# FM33L0XX register map
File version: 1.0
CPU: SC000 r1p0, little endian, no MPU, no FPU, 3 interrupt priority bits
Registers are 32-bit, read-write, reset 0x0 unless marked. A register's access mark holds for its fields unless they carry their own. Offsets are from the block's base; [hi:lo] are bit positions; {n}, {i} and the like mark numbered series; 'fields as' and 'values as' point back to an identical list.

## DMA — Peripheral DMA, Direct Memory Access
Base 0x40000400
0x00 GCR — Global Control Register
  [0] EN — DMA Global enable bit
    0=DISABLE (DMA is disable); 1=ENABLE (DMA is enable)
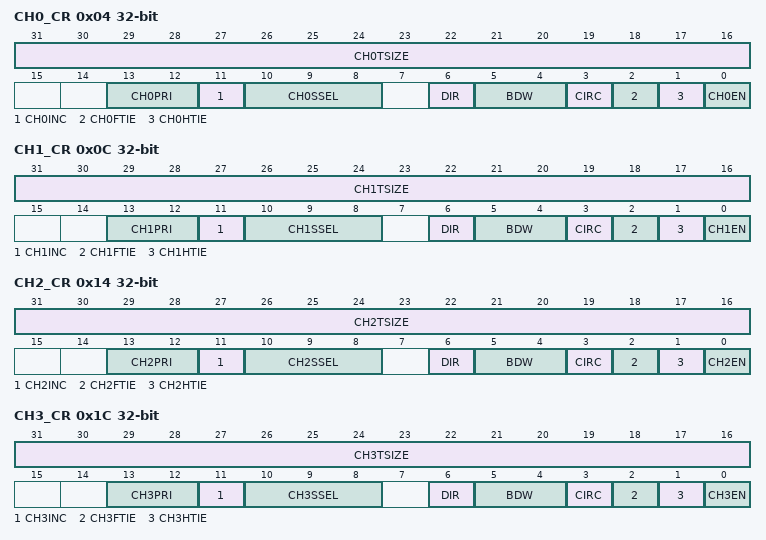
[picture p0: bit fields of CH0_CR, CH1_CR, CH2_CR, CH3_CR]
0x04 CH0_CR — DMA CH0 control Register
  [31:16] CH0TSIZE — channel0 transmit size setting
  [13:12] CH0PRI — channel0 priority setting
    0=LOW (channel0's priority is low); 1=Medium (channel0's priority is Medium); 2=High (channel0's priority is High); 3=Very High (channel0's priority is Very High)
  [11] CH0INC — channel0 RAM address increase setting
    0=DECREASE (channel0 RAM address decrease); 1=INCREASE (channel0 RAM address increase)
  [10:8] CH0SSEL — channel0 periph source select
    0=ADC (ADC data); 1=LPUART0_RX (LPUART0_RX data); 2=LPUART1_TX (LPUART1_TX data); 3=AES_IN (AES_IN data); 4=CRC (CRC data); 5=ATIM_CH1 (ATIM_CH1 data); 6=GTIM0_CH1 (GTIM0_CH1 data); 7=GTIM1_CH1 (GTIM1_CH1 data)
  [6] DIR — transfer direction
    0=perip to ram; 1=ram to perip
  [5:4] BDW — byte width select
    0=byte; 1=half_word; 1=word
  [3] CIRC — CIRC EN
    0=DISABLE (CIRC disable); 1=ENABLE (CIRC enable)
  [2] CH0FTIE — channel0 full transmit interrupt enable bit
    0=DISABLE (CH0 full transmit interrupt disable); 1=ENABLE (CH0 full transmit interrupt enable)
  [1] CH0HTIE — channel0 half transmit interrupt enable bit
    0=DISABLE (CH0 half transmit interrupt disable); 1=ENABLE (CH0 half transmit interrupt enable)
  [0] CH0EN — channel0 enable bit
    0=DISABLE (CH0 disable); 1=ENABLE (CH0 enable)
0x08 CH0_MAD — DMA channel0 RAM address Register
  [31:0] CH0RAMAD — CH0 RAM address
0x0C CH1_CR — DMA CH1 control Register
  [31:16] CH1TSIZE — channel1 transmit size setting
  [13:12] CH1PRI — channel1 priority setting
    0=LOW (channel1's priority is low); 1=Medium (channel1's priority is Medium); 2=High (channel1's priority is High); 3=Very High (channel1's priority is Very High)
  [11] CH1INC — channel1 RAM address increase setting
    0=DECREASE (channel1 RAM address decrease); 1=INCREASE (channel1 RAM address increase)
  [10:8] CH1SSEL — channel1 periph source select
    0=RXD0 (UART0_RXD data); 1=LPUART0_TX (LPUART0_TX data); 2=I2C_RX (I2C_RX data); 3=AES_OUT (AES_OUT data); 4=ATIM_CH2 (ATIM_CH2 data); 5=GTIM0_CH2 (GTIM0_CH2 data); 6=GTIM1_CH2 (GTIM1_CH2 data); 7=LPT32_CH1 (LPT32_CH1 data)
  [6] DIR — transfer direction
    0=perip to ram; 1=ram to perip
  [5:4] BDW — byte width select
    0=byte; 1=half_word; 1=word
  [3] CIRC — CIRC EN
    0=DISABLE (CIRC disable); 1=ENABLE (CIRC enable)
  [2] CH1FTIE — channel1 full transmit interrupt enable bit
    0=DISABLE (CH1 full transmit interrupt disable); 1=ENABLE (CH1 full transmit interrupt enable)
  [1] CH1HTIE — channel1 half transmit interrupt enable bit
    0=DISABLE (CH1 half transmit interrupt disable); 1=ENABLE (CH1 half transmit interrupt enable)
  [0] CH1EN — channel1 enable bit
    0=DISABLE (CH1 disable); 1=ENABLE (CH1 enable)
0x10 CH1_MAD — DMA channel1 RAM address Register
  [31:0] CH1MEMAD — CH1 RAM address
0x14 CH2_CR — DMA CH2 control Register
  [31:16] CH2TSIZE — channel2 transmit size setting
  [13:12] CH2PRI — channel2 priority setting
    0=LOW (channel2's priority is low); 1=Medium (channel2's priority is Medium); 2=High (channel2's priority is High); 3=Very High (channel2's priority is Very High)
  [11] CH2INC — channel2 RAM address increase setting
    0=DECREASE (channel2 RAM address decrease); 1=INCREASE (channel2 RAM address increase)
  [10:8] CH2SSEL — channel2 periph source select
    0=SPI2_RX (SPI2_RX data); 1=TXD0 (UART0_TXD data); 2=RXD4 (UART4_RXD data); 3=LPUART1_RX (LPUART1_RX data); 4=I2C_TX (I2C_TX data); 5=ATIM_CH3 (ATIM_CH3 data); 6=GTIM0_CH3 (GTIM0_CH3 data); 7=GTIM1_CH3 (GTIM1_CH3 data)
  [6] DIR — transfer direction
    0=perip to ram; 1=ram to perip
  [5:4] BDW — byte width select
    0=byte; 1=half_word; 1=word
  [3] CIRC — CIRC EN
    0=DISABLE (CIRC disable); 1=ENABLE (CIRC enable)
  [2] CH2FTIE — channel2 full transmit interrupt enable bit
    0=DISABLE (CH2 full transmit interrupt disable); 1=ENABLE (CH2 full transmit interrupt enable)
  [1] CH2HTIE — channel2 half transmit interrupt enable bit
    0=DISABLE (CH2 half transmit interrupt disable); 1=ENABLE (CH2 half transmit interrupt enable)
  [0] CH2EN — channel2 enable bit
    0=DISABLE (CH2 disable); 1=ENABLE (CH2 enable)
0x18 CH2_MAD — DMA channel2 RAM address Register
  [31:0] CH2RAMAD — CH2 RAM address
0x1C CH3_CR — DMA CH3 control Register
  [31:16] CH3TSIZE — channel3 transmit size setting
  [13:12] CH3PRI — channel3 priority setting
    0=LOW (channel3's priority is low); 1=Medium (channel3's priority is Medium); 2=High (channel3's priority is High); 3=Very High (channel3's priority is Very High)
  [11] CH3INC — channel3 RAM address increase setting
    0=DECREASE (channel3 RAM address decrease); 1=INCREASE (channel3 RAM address increase)
  [10:8] CH3SSEL — channel3 periph source select
    0=SPI1_RX (SPI1_RX data); 1=RXD0 (UART0_RXD data); 2=RXD1 (UART1_RXD data); 3=TXD4 (UART4_TXD data); 4=LPUART0_RX (LPUART0_RX data); 5=ATIM_CH4 (ATIM_CH4 data); 6=GTIM1_CH4 (GTIM0_CH4 data); 7=GTIM2_CH4 (GTIM1_CH4 data)
  [6] DIR — transfer direction
    0=perip to ram; 1=ram to perip
  [5:4] BDW — byte width select
    0=byte; 1=half_word; 1=word
  [3] CIRC — CIRC EN
    0=DISABLE (CIRC disable); 1=ENABLE (CIRC enable)
  [2] CH3FTIE — channel3 full transmit interrupt enable bit
    0=DISABLE (CH3 full transmit interrupt disable); 1=ENABLE (CH3 full transmit interrupt enable)
  [1] CH3HTIE — channel3 half transmit interrupt enable bit
    0=DISABLE (CH3 half transmit interrupt disable); 1=ENABLE (CH3 half transmit interrupt enable)
  [0] CH3EN — channel3 enable bit
    0=DISABLE (CH3 disable); 1=ENABLE (CH3 enable)
0x20 CH3_AD — DMA channel3 RAM address Register
  [31:0] CH3MEMAD — CH3 RAM address
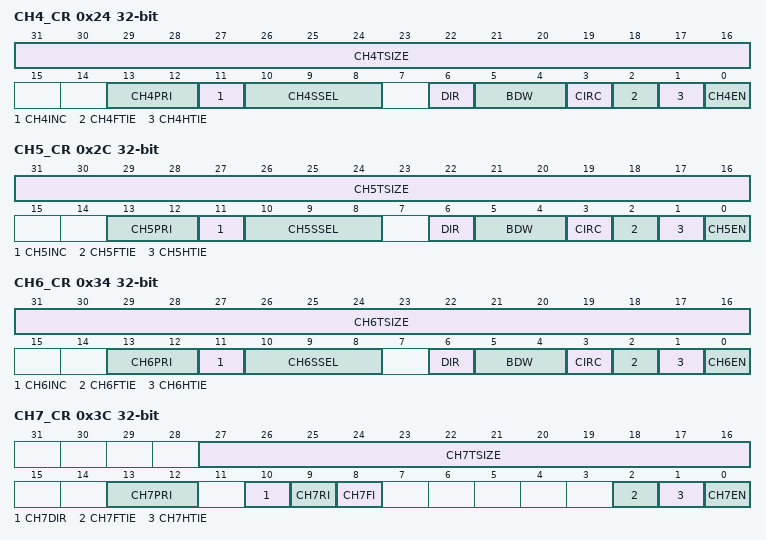
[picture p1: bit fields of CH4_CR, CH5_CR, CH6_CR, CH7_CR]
0x24 CH4_CR — DMA CH4 control Register
  [31:16] CH4TSIZE — channel4 transmit size setting
  [13:12] CH4PRI — channel4 priority setting
    0=LOW (channel4's priority is low); 1=Medium (channel4's priority is Medium); 2=High (channel4's priority is High); 3=Very High (channel4's priority is Very High)
  [11] CH4INC — channel4 RAM address increase setting
    0=DECREASE (channel4 RAM address decrease); 1=INCREASE (channel4 RAM address increase)
  [10:8] CH4SSEL — channel4 periph source select
    0=ADC (ADC data); 1=SPI1_TX (SPI1_TX data); 2=SPI2_TX (SPI2_TX data); 3=TXD0 (UART0_TXD data); 4=TXD1 (UART1_TXD data); 5=RXD5 (UART5_RXD data); 6=I2C_RX (I2C_RX data); 7=ATIM_TRIG (ATIM_TRIG data)
  [6] DIR — transfer direction
    0=perip to ram; 1=ram to perip
  [5:4] BDW — byte width select
    0=byte; 1=half_word; 1=word
  [3] CIRC — CIRC EN
    0=DISABLE (CIRC disable); 1=ENABLE (CIRC enable)
  [2] CH4FTIE — channel4 full transmit interrupt enable bit
    0=DISABLE (CH4 full transmit interrupt disable); 1=ENABLE (CH4 full transmit interrupt enable)
  [1] CH4HTIE — channel4 half transmit interrupt enable bit
    0=DISABLE (CH4 half transmit interrupt disable); 1=ENABLE (CH4 half transmit interrupt enable)
  [0] CH4EN — channel4 enable bit
    0=DISABLE (CH4 disable); 1=ENABLE (CH4 enable)
{0x8+8i} CH{i}_MAD (i=4..6) — DMA channel{i} RAM address Register
  [31:0] CH{i}MEMAD — CH{i} RAM address
0x2C CH5_CR — DMA CH5 control Register
  [31:16] CH5TSIZE — channel5 transmit size setting
  [13:12] CH5PRI — channel5 priority setting
    0=LOW (channel5's priority is low); 1=Medium (channel5's priority is Medium); 2=High (channel5's priority is High); 3=Very High (channel5's priority is Very High)
  [11] CH5INC — channel5 RAM address increase setting
    0=DECREASE (channel5 RAM address decrease); 1=INCREASE (channel5 RAM address increase)
  [10:8] CH5SSEL — channel5 periph source select
    0=SPI1_RX (SPI1_RX data); 1=SPI2_RX (SPI2_RX data); 2=RXD1 (UART1_RXD data); 3=LPUART0_TX (LPUART0_TX data); 4=LPUART1_RX (LPUART1_RX data); 5=U7816RX (U7816RX data); 6=GTIM1_TRI (GTIM1_TRI data); 7=LPT32_CH2 (LPT32_CH2 data)
  [6] DIR — transfer direction
    0=perip to ram; 1=ram to perip
  [5:4] BDW — byte width select
    0=byte; 1=half_word; 1=word
  [3] CIRC — CIRC EN
    0=DISABLE (CIRC disable); 1=ENABLE (CIRC enable)
  [2] CH5FTIE — channel5 full transmit interrupt enable bit
    0=DISABLE (CH5 full transmit interrupt disable); 1=ENABLE (CH5 full transmit interrupt enable)
  [1] CH5HTIE — channel5 half transmit interrupt enable bit
    0=DISABLE (CH5 half transmit interrupt disable); 1=ENABLE (CH5 half transmit interrupt enable)
  [0] CH5EN — channel5 enable bit
    0=DISABLE (CH5 disable); 1=ENABLE (CH5 enable)
0x34 CH6_CR — DMA CH6 control Register
  [31:16] CH6TSIZE — channel6 transmit size setting
  [13:12] CH6PRI — channel6 priority setting
    0=LOW (channel6's priority is low); 1=Medium (channel6's priority is Medium); 2=High (channel6's priority is High); 3=Very High (channel6's priority is Very High)
  [11] CH6INC — channel6 RAM address increase setting
    0=DECREASE (channel6 RAM address decrease); 1=INCREASE (channel6 RAM address increase)
  [10:8] CH6SSEL — channel6 periph source select
    0=SPI1_TX (SPI1_TX data); 1=SPI2_TX (SPI2_TX data); 2=TXD1 (UART1_TXD data); 3=TXD5 (UART5_TXD data); 4=LPUART1_TX (LPUART1_TX data); 5=U7816TX (U7816TX data); 6=I2C_TX (I2C_TX data); 7=GTIM_TRIG (GTIM_TRIG data)
  [6] DIR — transfer direction
    0=perip to ram; 1=ram to perip
  [5:4] BDW — byte width select
    0=byte; 1=half_word; 1=word
  [3] CIRC — CIRC EN
    0=DISABLE (CIRC disable); 1=ENABLE (CIRC enable)
  [2] CH6FTIE — channel6 full transmit interrupt enable bit
    0=DISABLE (CH6 full transmit interrupt disable); 1=ENABLE (CH6 full transmit interrupt enable)
  [1] CH6HTIE — channel6 half transmit interrupt enable bit
    0=DISABLE (CH6 half transmit interrupt disable); 1=ENABLE (CH6 half transmit interrupt enable)
  [0] CH6EN — channel6 enable bit
    0=DISABLE (CH6 disable); 1=ENABLE (CH6 enable)
0x3C CH7_CR — DMA CH7 control Register
  [27:16] CH7TSIZE — channel7 transmit size setting(fixed size 64 when transmits from ram to flash )
  [13:12] CH7PRI — channel7 priority setting
    0=LOW (channel7's priority is low); 1=Medium (channel7's priority is Medium); 2=High (channel7's priority is High); 3=Very High (channel7's priority is Very High)
  [10] CH7DIR — channel7 transmit direction setting
    0=RAM2FLASH (from RAM to flash); 1=FLASH2RAM (FROM flash to RAM)
  [9] CH7RI — channel7 RAM address increase setting
    0=DECREASE (channel7 RAM address decrease); 1=INCREASE (channel7 RAM address increase)
  [8] CH7FI — channel7 flash address increase setting
    0=DECREASE (channel7 flash address decrease); 1=INCREASE (channel7 flash address increase)
  [2] CH7FTIE — channel7 full transmit interrupt enable bit
    0=DISABLE (CH7 full transmit interrupt disable); 1=ENABLE (CH7 full transmit interrupt enable)
  [1] CH7HTIE — channel7 half transmit interrupt enable bit
    0=DISABLE (CH7 half transmit interrupt disable); 1=ENABLE (CH7 half transmit interrupt enable)
  [0] CH7EN — channel7 enable bit
    0=DISABLE (CH7 disable); 1=ENABLE (CH7 enable)
0x40 CH7_FLSAD — DMA channel7 flash address Register
  [14:0] CH7FLSAD — CH7 flash address
0x44 CH7_RAMAD — DMA channel7 RAM address Register
  [11:0] CH7RAMAD — CH7 RAM address
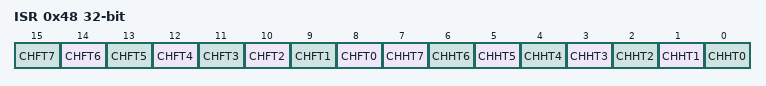
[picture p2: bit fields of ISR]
0x48 ISR — DMA status Register
  [n+8] CHFT{n} (n=0..7) — channel{n} transmit status bit
    0=NOT_FINISH (channel{n} transmit - not start/not finish); 1=FINISH (channel{n} transmit - finish)
  [n] CHHT{n} (n=3..7) — channel{n} half transmit status bit
    0=NOT_FINISH (channel{n} half transmit - not start/not finish); 1=FINISH (channel{n} half transmit - finish)
  [2] CHHT2 — channel2 half transmit status bit
    0=NOT_FINISH (channel1 half transmit - not start/not finish); 1=FINISH (channel1 half transmit - finish)
  [1] CHHT1 — channel1 half transmit status bit
    values as CHHT2
  [0] CHHT0 — channel0 half transmit status bit
    0=NOT_FINISH (channel0 half transmit - not start/not finish); 1=FINISH (channel0 half transmit - finish)
